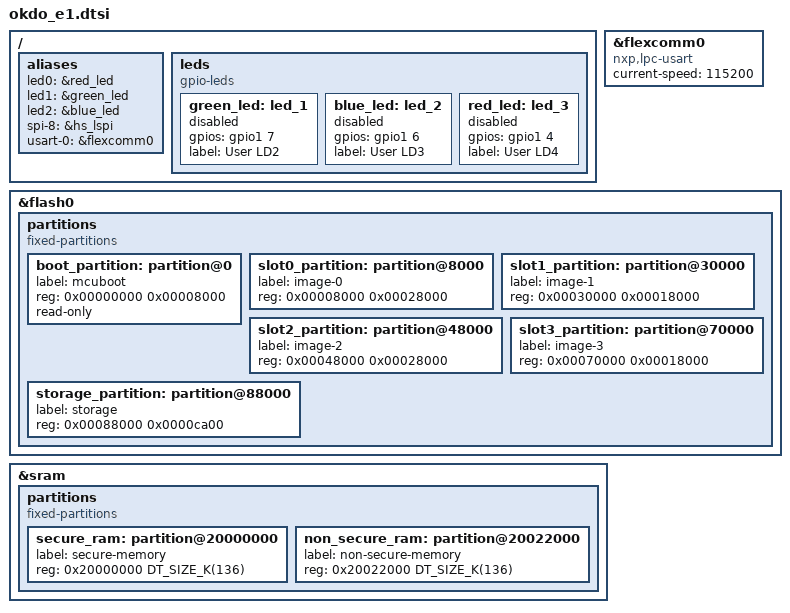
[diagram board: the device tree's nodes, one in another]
/*
 * Copyright (c) 2019, NXP
 *
 * SPDX-License-Identifier: Apache-2.0
 */

/ {
	aliases{
		led0 = &red_led;
		led1 = &green_led;
		led2 = &blue_led;
		spi-8 = &hs_lspi;
		usart-0 = &flexcomm0;
	};

	leds {
		compatible = "gpio-leds";
		green_led: led_1 {
			gpios = <&gpio1 7 0>;
			label = "User LD2";
			status = "disabled";
		};
		blue_led: led_2 {
			gpios = <&gpio1 6 0>;
			label = "User LD3";
			status = "disabled";
		};
		red_led: led_3 {
			gpios = <&gpio1 4 0>;
			label = "User LD4";
			status = "disabled";
		};
	};
};

&flexcomm0 {
	compatible = "nxp,lpc-usart";
	current-speed = <115200>;
};

&flash0 {

	partitions {
		compatible = "fixed-partitions";
		#address-cells = <1>;
		#size-cells = <1>;
		/* Please enable mcuboot's swap move, no scratch */

		boot_partition: partition@0 {
			label = "mcuboot";
			reg = <0x00000000 0x00008000>;
			read-only;
		};
		slot0_partition: partition@8000 {
			label = "image-0";
			reg = <0x00008000 0x00028000>;
		};
		slot1_partition: partition@30000 {
			label = "image-1";
			reg = <0x00030000 0x00018000>;
		};
		slot2_partition: partition@48000 {
			label = "image-2";
			reg = <0x00048000 0x00028000>;
		};
		slot3_partition: partition@70000 {
			label = "image-3";
			reg = <0x00070000 0x00018000>;
		};
		/*
		 * The flash starting at 0x88000 and ending at
		 * 0x949FF is reserved for the application.
		 */
		storage_partition: partition@88000 {
			label = "storage";
			reg = <0x00088000 0x0000ca00>;
		};
	};
};

&sram {
	partitions {
		compatible = "fixed-partitions";
		#address-cells = <1>;
		#size-cells = <1>;

		/* RAM split used by TFM */
		secure_ram: partition@20000000 {
			label = "secure-memory";
			reg = <0x20000000 DT_SIZE_K(136)>;
		};

		non_secure_ram: partition@20022000 {
			label = "non-secure-memory";
			reg = <0x20022000 DT_SIZE_K(136)>;
		};
	};
};

